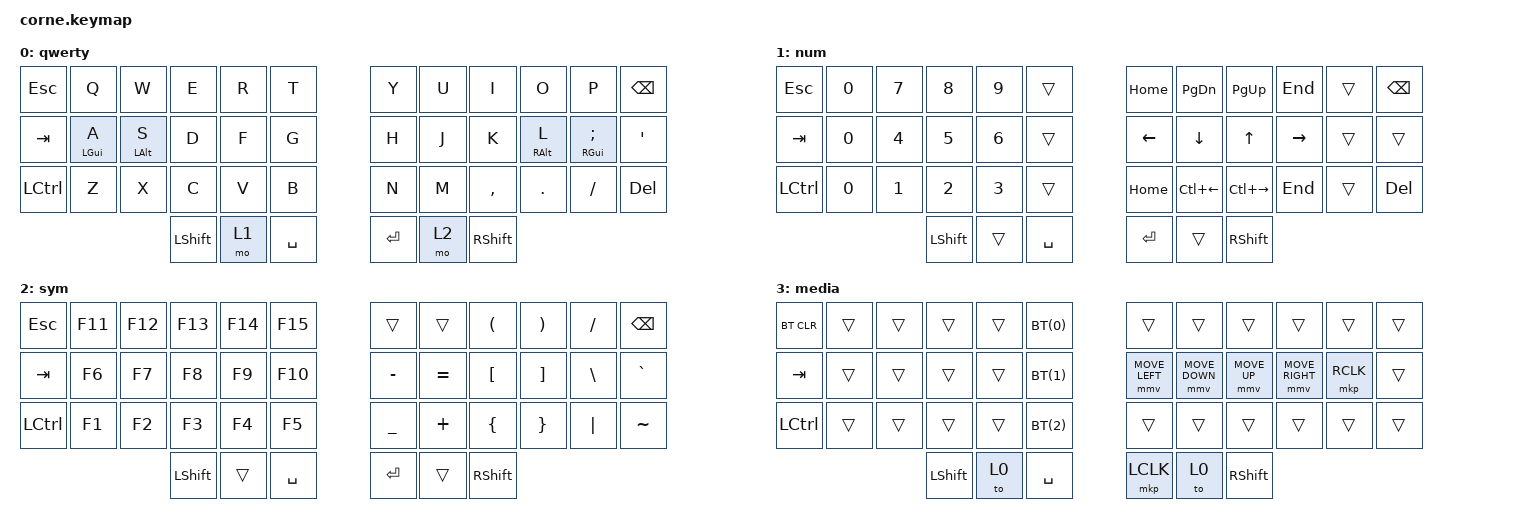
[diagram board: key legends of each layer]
/*
 * Copyright (c) 2020 The ZMK Contributors
 *
 * SPDX-License-Identifier: MIT
 */

#include <behaviors.dtsi>
#include <dt-bindings/zmk/keys.h>
#include <dt-bindings/zmk/bt.h>
#include <dt-bindings/zmk/pointing.h>

#include "zmk-helpers/helper.h"
#include "zmk-helpers/key-labels-42.h"

#define ___ &trans

#define RPI(kp0, kp1) &rpi kp0 kp1 
#define BT(num) &bt BT_SEL num 

#define DEFAULT 0
#define NUM     1
#define SYM     2
#define MEDIA   3

/* Timeless homerow mods */

// https://github.com/urob/zmk-config/tree/main#timeless-homerow-mods
#define KEYS_L LT0 LT1 LT2 LT3 LT4 LM0 LM1 LM2 LM3 LM4 LB0 LB1 LB2 LB3 LB4  // left hand
#define KEYS_R RT0 RT1 RT2 RT3 RT4 RM0 RM1 RM2 RM3 RM4 RB0 RB1 RB2 RB3 RB4  // right hand
#define THUMBS LH1 LH0 RH0 RH1            

ZMK_HOLD_TAP(hml,
    flavor = "balanced";
    tapping-term-ms = <280>;
    require-prior-idle-ms = <150>;
    hold-trigger-key-positions = <KEYS_R THUMBS>;
    hold-trigger-on-release;
    bindings = <&kp>, <&kp>;
)

ZMK_HOLD_TAP(hmr,
    flavor = "balanced";
    tapping-term-ms = <280>;
    require-prior-idle-ms = <150>;
    hold-trigger-key-positions = <KEYS_L THUMBS>;
    hold-trigger-on-release;
    bindings = <&kp>, <&kp>;
)


/ {
        conditional_layers {
            compatible = "zmk,conditional-layers";
            tri_layer {
                if-layers = <NUM SYM>;
                then-layer = <MEDIA>;
            };
        };

        macros {
            walrus: walrus {
                compatible = "zmk,behavior-macro";
                #binding-cells = <0>;
                bindings
                    = <&macro_tap &kp COLON &kp EQUAL>
                    ;
            };
        };

        behaviors {
            mt: mod_tap {
                compatible = "zmk,behavior-hold-tap";
                #binding-cells = <2>;
                flavor = "balanced";
                tapping-term-ms = <200>;
                quick-tap-ms = <150>;
                global-quick-tap;
                bindings = <&kp>, <&kp>;
                display-name = "Mod-Tap";
            };

            rpi: require_prior_idle {
                compatible = "zmk,behavior-hold-tap";
                #binding-cells = <2>;
                flavor = "tap-preferred";
                tapping-term-ms = <300>;
                quick-tap-ms = <300>;
                require-prior-idle-ms = <125>;
                bindings = <&kp>, <&kp>;
                display-name = "Require-Prior-Idle";
            };

            td_eq_walrus: tap_dance_equal_walrus {
                compatible = "zmk,behavior-tap-dance";
                #binding-cells = <0>;
                tapping-term-ms = <150>;
                bindings = <&kp EQUAL>, <&walrus>;
            };
        };

        keymap {
            compatible = "zmk,keymap";

            default_layer {
                display-name = "qwerty";
	            bindings = <
// ╭──────────────┬──────────────┬──────────────┬──────────────┬──────────────┬──────────────╮      ╭──────────────┬──────────────┬──────────────┬──────────────┬──────────────┬──────────────╮
// | ESC          | Q            | W            | E            | R            | T            |      | Y            | U            | I            | O            | P            | BSPC         |
     &kp ESC        &kp Q          &kp W          &kp E          &kp R          &kp T                 &kp Y          &kp U          &kp I          &kp O          &kp P          &kp BSPC
// ├──────────────┼──────────────┼──────────────┼──────────────┼──────────────┼──────────────┤      ├──────────────┼──────────────┼──────────────┼──────────────┼──────────────┼──────────────┤
// | TAB          | A            | S            | D            | F            | G            |      | H            | J            | K            | L            | ;            | '            |
     &kp TAB        &hml LGUI A    &hml LALT S    &kp D          &kp F          &kp G                 &kp H          &kp J          &kp K          &hmr RALT L    &hmr RGUI SEMI &kp SQT
// ├──────────────┼──────────────┼──────────────┼──────────────┼──────────────┼──────────────┤      ├──────────────┼──────────────┼──────────────┼──────────────┼──────────────┼──────────────┤
// | CTRL         | Z            | X            | C            | V            | B            |      | N            | M            | ,            | .            | /            | DEL          |
     &kp LCTRL      &kp Z          &kp X          &kp C          &kp V          &kp B                 &kp N          &kp M          &kp COMMA      &kp DOT        &kp FSLH       &kp DEL
// ╰──────────────┴──────────────┴──────────────┼──────────────┼──────────────┼──────────────┤      ├──────────────┼──────────────┼──────────────┼──────────────┴──────────────┴──────────────╯
//                                              | SHFT         | LWR          | SPC          |      | ENT          | RSE          | SHFT         |
                                                  &kp LSHFT      &mo 1          &kp SPACE             &kp RET        &mo 2          &kp RSHFT
//                                              ╰──────────────┴──────────────┴──────────────╯      ╰──────────────┴──────────────┴──────────────╯
                >;
            };

            lower_layer {
                display-name = "num";
	            bindings = <
// ╭──────────────┬──────────────┬──────────────┬──────────────┬──────────────┬──────────────╮      ╭──────────────┬──────────────┬──────────────┬──────────────┬──────────────┬──────────────╮
// | ESC          | 0            | 7 &          | 8 *          | 9            |              |      |              |              |              |              |              | BSPC         |
     &kp ESC        &kp N0         &kp N7         &kp N8         &kp N9         ___                   &kp HOME       &kp PG_DN      &kp PG_UP      &kp END        ___            &kp BSPC
// ├──────────────┼──────────────┼──────────────┼──────────────┼──────────────┼──────────────┤      ├──────────────┼──────────────┼──────────────┼──────────────┼──────────────┼──────────────┤
// | TAB          | 0            | 4 $          | 5 %          | 6 ^          |              |      | LEFT         | DOWN         | UP           | RIGHT        |              |              |
     &kp TAB        &kp N0         &kp N4         &kp N5         &kp N6         ___                   &kp LEFT       &kp DOWN       &kp UP         &kp RIGHT      ___            ___
// ├──────────────┼──────────────┼──────────────┼──────────────┼──────────────┼──────────────┤      ├──────────────┼──────────────┼──────────────┼──────────────┼──────────────┼──────────────┤
// | CTRL         | 0            | 1 !          | 2 @          | 3 #          |              |      |              | CTRL+LEFT    | CTRL+RIGHT   |              |              | DEL          |
     &kp LCTRL      &kp N0         &kp N1         &kp N2         &kp N3         ___                   &kp HOME       &kp LC(LEFT)   &kp LC(RIGHT)  &kp END        ___            &kp DEL
// ╰──────────────┴──────────────┴──────────────┼──────────────┼──────────────┼──────────────┤      ├──────────────┼──────────────┼──────────────┼──────────────┴──────────────┴──────────────╯
//                                              | SHFT         |              | SPC          |      | ENT          |              | SHFT         |
                                                  &kp LSHFT      ___            &kp SPACE             &kp RET        ___            &kp RSHFT
//                                              ╰──────────────┴──────────────┴──────────────╯      ╰──────────────┴──────────────┴──────────────╯

                >;
            };

            raise_layer {
                display-name = "sym";
	            bindings = <
// ╭──────────────┬──────────────┬──────────────┬──────────────┬──────────────┬──────────────╮      ╭──────────────┬──────────────┬──────────────┬──────────────┬──────────────┬──────────────╮
// | ESC          | F11          | F12          | F13          | F14          | F15          |      |              |              | (            | )            | /            | BSPC         |
     &kp ESC        &kp F11        &kp F12        &kp F13        &kp F14        &kp F15               ___            ___            &kp LPAR       &kp RPAR       &kp FSLH       &kp BSPC
// ├──────────────┼──────────────┼──────────────┼──────────────┼──────────────┼──────────────┤      ├──────────────┼──────────────┼──────────────┼──────────────┼──────────────┼──────────────┤
// | TAB          | F6           | F7           | F8           | F9           | F10          |      | -            | =            | [            | ]            | \            | `            |
     &kp TAB        &kp F6         &kp F7         &kp F8         &kp F9         &kp F10               &kp MINUS      &kp EQUAL      &kp LBKT       &kp RBKT       &kp BSLH       &kp GRAVE
// ├──────────────┼──────────────┼──────────────┼──────────────┼──────────────┼──────────────┤      ├──────────────┼──────────────┼──────────────┼──────────────┼──────────────┼──────────────┤
// | CTRL         | F1           | F2           | F3           | F4           | F5           |      | _            | +            | {            | }            | |            | ~            |
     &kp LCTRL      &kp F1         &kp F2         &kp F3         &kp F4         &kp F5                &kp UNDER      &kp PLUS       &kp LBRC       &kp RBRC       &kp PIPE       &kp TILDE
// ╰──────────────┴──────────────┴──────────────┼──────────────┼──────────────┼──────────────┤      ├──────────────┼──────────────┼──────────────┼──────────────┴──────────────┴──────────────╯
//                                              | SHFT         |              | SPC          |      | ENT          |              | SHFT         |
                                                  &kp LSHFT      ___            &kp SPACE             &kp RET        ___            &kp RSHFT
//                                              ╰──────────────┴──────────────┴──────────────╯      ╰──────────────┴──────────────┴──────────────╯
                >;
            };


            bt_and_media_layer {
                display-name = "media";
	            bindings = <
// ╭──────────────┬──────────────┬──────────────┬──────────────┬──────────────┬──────────────╮      ╭──────────────┬──────────────┬──────────────┬──────────────┬──────────────┬──────────────╮
// | BT_CLR       |              |              |              |              | BT0          |      |              |              |              |              |              |              |
     &bt BT_CLR     ___            ___            ___            ___            BT(0)                 ___            ___            ___            ___            ___            ___
// ├──────────────┼──────────────┼──────────────┼──────────────┼──────────────┼──────────────┤      ├──────────────┼──────────────┼──────────────┼──────────────┼──────────────┼──────────────┤
// | TAB          |              |              |              |              | BT1          |      |              |              |              |              | RCLK         |              |
     &kp TAB        ___            ___            ___            ___            BT(1)                &mmv MOVE_LEFT &mmv MOVE_DOWN  &mmv MOVE_UP  &mmv MOVE_RIGHT &mkp RCLK      ___
// ├──────────────┼──────────────┼──────────────┼──────────────┼──────────────┼──────────────┤      ├──────────────┼──────────────┼──────────────┼──────────────┼──────────────┼──────────────┤
// | CTRL         |              |              |              |              | BT2          |      |              |              |              |              |              |              |
     &kp LCTRL      ___            ___            ___            ___            BT(2)                 ___            ___            ___            ___            ___            ___
// ╰──────────────┴──────────────┴──────────────┼──────────────┼──────────────┼──────────────┤      ├──────────────┼──────────────┼──────────────┼──────────────┴──────────────┴──────────────╯
//                                              | SHFT         |              | SPC          |      | LCLK         |              | SHFT         |
                                                  &kp LSHFT      &to 0          &kp SPACE             &mkp LCLK        &to 0          &kp RSHFT
//                                              ╰──────────────┴──────────────┴──────────────╯      ╰──────────────┴──────────────┴──────────────╯


                >;
            };
        };
};
